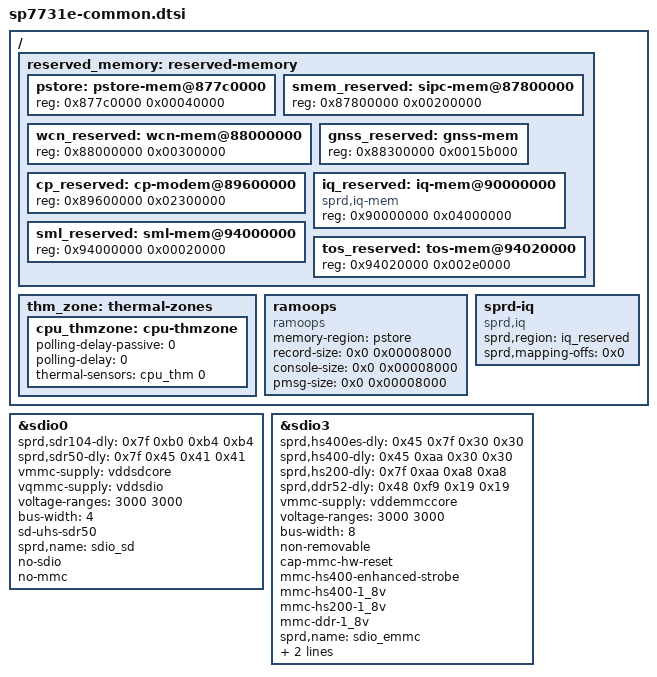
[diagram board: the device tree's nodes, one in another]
/*
 * Unisoc SP7731e board common DTS file
 *
 * Copyright (C) 2019, Unisoc Communications Inc.
 *
 * This file is licensed under a dual GPLv2 or X11 license.
 */

/ {
	reserved_memory: reserved-memory {
		#address-cells = <1>;
		#size-cells = <1>;
		ranges;

		pstore: pstore-mem@877c0000 {
			reg = <0x877c0000 0x00040000>;
		};

		smem_reserved: sipc-mem@87800000 {
			reg = <0x87800000 0x00200000>;
		};

		/*start address must be 32M aligned */
		wcn_reserved: wcn-mem@88000000 {
			reg = <0x88000000 0x00300000>;
		};

		gnss_reserved: gnss-mem {
			reg = <0x88300000 0x0015b000>;
		};

		cp_reserved: cp-modem@89600000 {
			reg = <0x89600000 0x02300000>;
		};

		/* only used for iq, will be removed in normal mode by uboot */
		iq_reserved: iq-mem@90000000 {
			compatible = "sprd,iq-mem";
			reg = <0x90000000 0x04000000>;
		};

		/*start address must be 64M aligned */
		sml_reserved: sml-mem@94000000 {
			reg = <0x94000000 0x00020000>;
		};

		tos_reserved: tos-mem@94020000 {
			reg = <0x94020000 0x002e0000>;
		};
	};

	thm_zone: thermal-zones {
		cpu_thmzone: cpu-thmzone {
			polling-delay-passive = <0>;
			polling-delay = <0>;
			thermal-sensors = <&cpu_thm 0>;
		};
	};

	ramoops {
		compatible = "ramoops";
		memory-region = <&pstore>;
		record-size	= <0x0 0x00008000>;
		console-size	= <0x0 0x00008000>;
		pmsg-size	= <0x0 0x00008000>;
	};

	sprd-iq {
		compatible = "sprd,iq";
		sprd,region = <&iq_reserved>;
		sprd,mapping-offs = <0x0>;
	};
};

&sdio0 {
	sprd,sdr104-dly = <0x7f 0xb0 0xb4 0xb4>;
	sprd,sdr50-dly = <0x7f 0x45 0x41 0x41>;
	vmmc-supply = <&vddsdcore>;
	vqmmc-supply = <&vddsdio>;
	voltage-ranges = <3000 3000>;
	bus-width = <4>;
	sd-uhs-sdr50;
	sprd,name = "sdio_sd";
	no-sdio;
	no-mmc;
	status = "okay";
};

&sdio3 {
	sprd,hs400es-dly = <0x45 0x7f 0x30 0x30>;
	sprd,hs400-dly = <0x45 0xaa 0x30 0x30>;
	sprd,hs200-dly = <0x7f 0xaa 0xa8 0xa8>;
	sprd,ddr52-dly = <0x48 0xf9 0x19 0x19>;
	vmmc-supply = <&vddemmccore>;
	voltage-ranges = <3000 3000>;
	bus-width = <8>;
	non-removable;
	cap-mmc-hw-reset;
	mmc-hs400-enhanced-strobe;
	mmc-hs400-1_8v;
	mmc-hs200-1_8v;
	mmc-ddr-1_8v;
	sprd,name = "sdio_emmc";
	no-sdio;
	no-sd;
	status = "okay";
};

